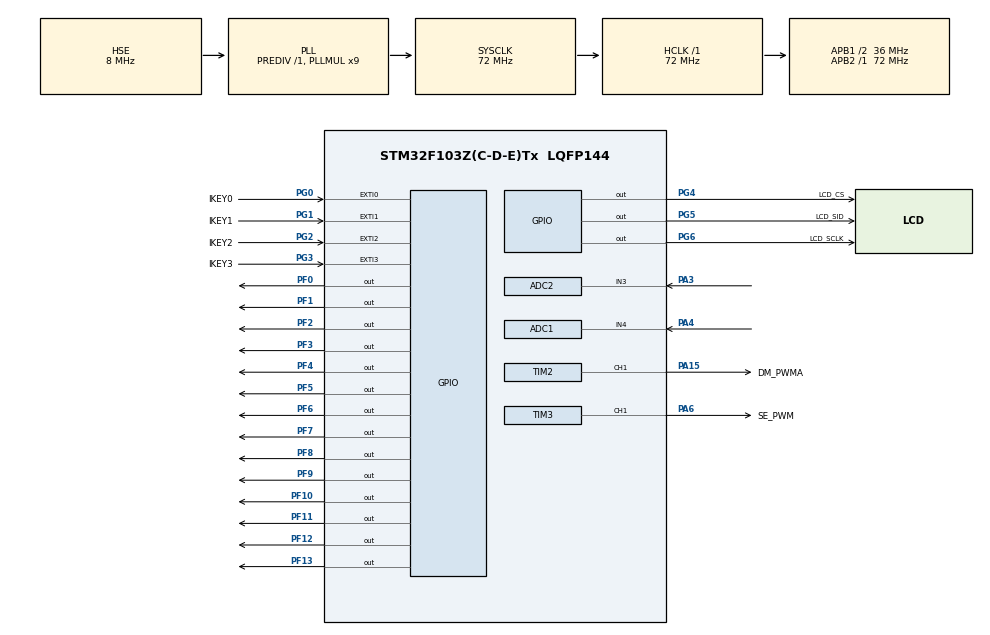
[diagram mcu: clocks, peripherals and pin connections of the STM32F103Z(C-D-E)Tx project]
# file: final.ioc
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ADC1.Channel-9\#ChannelRegularConversion=ADC_CHANNEL_4
ADC1.NbrOfConversionFlag=1
ADC1.Rank-9\#ChannelRegularConversion=1
ADC1.SamplingTime-9\#ChannelRegularConversion=ADC_SAMPLETIME_1CYCLE_5
ADC1.master=1
ADC2.Channel-0\#ChannelRegularConversion=ADC_CHANNEL_3
ADC2.NbrOfConversionFlag=1
ADC2.Rank-0\#ChannelRegularConversion=1
ADC2.SamplingTime-0\#ChannelRegularConversion=ADC_SAMPLETIME_1CYCLE_5
FREERTOS.Queues01=DataUpdateQueue,16,DataUpdateQueueItem,0,Dynamic,NULL,NULL
FREERTOS.Tasks01=default_task,8,128,start_task_default_task,Default,NULL,Dynamic,NULL,NULL;running_lights,10,128,start_task_running_lights,As weak,NULL,Dynamic,NULL,NULL;traffic_lights,10,128,start_task_traffic_lights,As weak,NULL,Dynamic,NULL,NULL;dc_motor,11,128,start_task_dc_motor,As weak,NULL,Dynamic,NULL,NULL;steering_engine,13,128,start_task_steering_engine,As external,NULL,Dynamic,NULL,NULL;lcd12864,14,128,start_task_lcd,As external,NULL,Dynamic,NULL,NULL;adc_pot,8,128,start_task_adc_pot,As external,NULL,Dynamic,NULL,NULL;adc_temp,8,128,start_task_adc_temp,As external,NULL,Dynamic,NULL,NULL
FREERTOS.configTOTAL_HEAP_SIZE=8192
Mcu.Family=STM32F1
Mcu.Name=STM32F103Z(C-D-E)Tx
Mcu.Package=LQFP144
NVIC.EXTI0_IRQn=true\:5\:0\:false\:false\:true\:false\:true\:true\:true
NVIC.EXTI1_IRQn=true\:5\:0\:false\:false\:true\:false\:true\:true\:true
NVIC.EXTI2_IRQn=true\:5\:0\:false\:false\:true\:false\:true\:true\:true
NVIC.EXTI3_IRQn=true\:5\:0\:false\:false\:true\:false\:true\:true\:true
NVIC.PriorityGroup=NVIC_PRIORITYGROUP_4
NVIC.RCC_IRQn=true\:5\:0\:false\:false\:true\:true\:true\:false\:true
NVIC.TIM1_UP_IRQn=true\:15\:0\:false\:false\:true\:false\:false\:true\:true
NVIC.TimeBase=TIM1_UP_IRQn
NVIC.TimeBaseIP=TIM1
OSC_IN.Mode=HSE-External-Oscillator
OSC_IN.Signal=RCC_OSC_IN
OSC_OUT.Mode=HSE-External-Oscillator
OSC_OUT.Signal=RCC_OSC_OUT
PA13.Mode=Serial_Wire
PA13.Signal=SYS_JTMS-SWDIO
PA14.Mode=Serial_Wire
PA14.Signal=SYS_JTCK-SWCLK
PA15.GPIO_Label=DM_PWMA
PA15.Signal=S_TIM2_CH1_ETR
PA3.Signal=ADCx_IN3
PA4.Signal=ADCx_IN4
PA6.GPIO_Label=SE_PWM
PA6.Signal=S_TIM3_CH1
PF0.Signal=GPIO_Output
PF1.Signal=GPIO_Output
PF10.Signal=GPIO_Output
PF11.Signal=GPIO_Output
PF12.Signal=GPIO_Output
PF13.Signal=GPIO_Output
PF2.Signal=GPIO_Output
PF3.Signal=GPIO_Output
PF4.Signal=GPIO_Output
PF5.Signal=GPIO_Output
PF6.Signal=GPIO_Output
PF7.Signal=GPIO_Output
PF8.Signal=GPIO_Output
PF9.Signal=GPIO_Output
PG0.GPIO_Label=IKEY0
PG0.GPIO_ModeDefaultEXTI=GPIO_MODE_IT_FALLING
PG0.Signal=GPXTI0
PG1.GPIO_Label=IKEY1
PG1.GPIO_ModeDefaultEXTI=GPIO_MODE_IT_FALLING
PG1.Signal=GPXTI1
PG2.GPIO_Label=IKEY2
PG2.GPIO_ModeDefaultEXTI=GPIO_MODE_IT_FALLING
PG2.Signal=GPXTI2
PG3.GPIO_Label=IKEY3
PG3.GPIO_ModeDefaultEXTI=GPIO_MODE_IT_FALLING
PG3.Signal=GPXTI3
PG4.GPIO_Label=LCD_CS
PG4.Signal=GPIO_Output
PG5.GPIO_Label=LCD_SID
PG5.Signal=GPIO_Output
PG6.GPIO_Label=LCD_SCLK
PG6.Signal=GPIO_Output
ProjectManager.HeapSize=0x200
ProjectManager.StackSize=0x400
ProjectManager.TargetToolchain=Makefile
RCC.ADCPresc=RCC_ADCPCLK2_DIV6
RCC.AHBFreq_Value=72000000
RCC.APB1CLKDivider=RCC_HCLK_DIV2
RCC.APB1Freq_Value=36000000
RCC.APB1TimFreq_Value=72000000
RCC.APB2Freq_Value=72000000
RCC.APB2TimFreq_Value=72000000
RCC.EnbaleCSS=true
RCC.HCLKFreq_Value=72000000
RCC.PLLMUL=RCC_PLL_MUL9
RCC.PLLSourceVirtual=RCC_PLLSOURCE_HSE
RCC.SYSCLKFreq_VALUE=72000000
RCC.SYSCLKSource=RCC_SYSCLKSOURCE_PLLCLK
RCC.USBFreq_Value=72000000
SH.ADCx_IN3.0=ADC2_IN3,IN3
SH.ADCx_IN4.0=ADC1_IN4,IN4
SH.S_TIM2_CH1_ETR.0=TIM2_CH1,PWM Generation1 CH1
SH.S_TIM3_CH1.0=TIM3_CH1,PWM Generation1 CH1
TIM2.Channel-PWM\ Generation1\ CH1=TIM_CHANNEL_1
TIM2.Period=1000-1
TIM2.Prescaler=72-1
TIM3.Channel-PWM\ Generation1\ CH1=TIM_CHANNEL_1
TIM3.Period=200 - 1
TIM3.Prescaler=7200-1
TIM3.Pulse-PWM\ Generation1\ CH1=0
VP_FREERTOS_VS_CMSIS_V2.Mode=CMSIS_V2
VP_SYS_VS_tim1.Mode=TIM1
board=custom

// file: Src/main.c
/* USER CODE BEGIN Header */
/**
 ******************************************************************************
 * @file           : main.c
 * @brief          : Main program body
 ******************************************************************************
 * @attention
 *
 * Copyright (c) 2024 STMicroelectronics.
 * All rights reserved.
 *
 * This software is licensed under terms that can be found in the LICENSE file
 * in the root directory of this software component.
 * If no LICENSE file comes with this software, it is provided AS-IS.
 *
 ******************************************************************************
 */
/* USER CODE END Header */
#include "main.h"
#include "adc.h"
#include "cmsis_os.h"
#include "gpio.h"
#include "tim.h"

/* USER CODE BEGIN Includes */
#include "cpp_main.hh"
/* USER CODE END Includes */

void SystemClock_Config(void);
void MX_FREERTOS_Init(void);

int main(void) {

  /* MCU Configuration--------------------------------------------------------*/

  /* Reset of all peripherals, Initializes the Flash interface and the Systick.
   */
  HAL_Init();

  /* Configure the system clock */
  SystemClock_Config();

  /* Initialize all configured peripherals */
  MX_GPIO_Init();
  MX_TIM2_Init();
  MX_TIM3_Init();
  MX_ADC1_Init();
  MX_ADC2_Init();
  /* USER CODE BEGIN 2 */
  cpp_main();
  /* USER CODE END 2 */

  /* Init scheduler */
  osKernelInitialize();

  /* Call init function for freertos objects (in cmsis_os2.c) */
  MX_FREERTOS_Init();

  /* Start scheduler */
  osKernelStart();

  /* We should never get here as control is now taken by the scheduler */

  /* Infinite loop */
  while (1) {

  }
}

void SystemClock_Config(void) {
  RCC_OscInitTypeDef RCC_OscInitStruct = {0};
  RCC_ClkInitTypeDef RCC_ClkInitStruct = {0};
  RCC_PeriphCLKInitTypeDef PeriphClkInit = {0};

  /** Initializes the RCC Oscillators according to the specified parameters
   * in the RCC_OscInitTypeDef structure.
   */
  RCC_OscInitStruct.OscillatorType = RCC_OSCILLATORTYPE_HSE;
  RCC_OscInitStruct.HSEState = RCC_HSE_ON;
  RCC_OscInitStruct.HSEPredivValue = RCC_HSE_PREDIV_DIV1;
  RCC_OscInitStruct.HSIState = RCC_HSI_ON;
  RCC_OscInitStruct.PLL.PLLState = RCC_PLL_ON;
  RCC_OscInitStruct.PLL.PLLSource = RCC_PLLSOURCE_HSE;
  RCC_OscInitStruct.PLL.PLLMUL = RCC_PLL_MUL9;
  if (HAL_RCC_OscConfig(&RCC_OscInitStruct) != HAL_OK) {
    Error_Handler();
  }

  /** Initializes the CPU, AHB and APB buses clocks
   */
  RCC_ClkInitStruct.ClockType = RCC_CLOCKTYPE_HCLK | RCC_CLOCKTYPE_SYSCLK |
                                RCC_CLOCKTYPE_PCLK1 | RCC_CLOCKTYPE_PCLK2;
  RCC_ClkInitStruct.SYSCLKSource = RCC_SYSCLKSOURCE_PLLCLK;
  RCC_ClkInitStruct.AHBCLKDivider = RCC_SYSCLK_DIV1;
  RCC_ClkInitStruct.APB1CLKDivider = RCC_HCLK_DIV2;
  RCC_ClkInitStruct.APB2CLKDivider = RCC_HCLK_DIV1;

  if (HAL_RCC_ClockConfig(&RCC_ClkInitStruct, FLASH_LATENCY_2) != HAL_OK) {
    Error_Handler();
  }
  PeriphClkInit.PeriphClockSelection = RCC_PERIPHCLK_ADC;
  PeriphClkInit.AdcClockSelection = RCC_ADCPCLK2_DIV6;
  if (HAL_RCCEx_PeriphCLKConfig(&PeriphClkInit) != HAL_OK) {
    Error_Handler();
  }

  /** Enables the Clock Security System
   */
  HAL_RCC_EnableCSS();
}

void HAL_TIM_PeriodElapsedCallback(TIM_HandleTypeDef *htim) {
  if (htim->Instance == TIM1) {
    HAL_IncTick();
  }
}

void Error_Handler(void) {
  __disable_irq();
  while (1) {
  }
}

#ifdef USE_FULL_ASSERT
/**
 * @brief  Reports the name of the source file and the source line number
 *         where the assert_param error has occurred.
 * @param  file: pointer to the source file name
 * @param  line: assert_param error line source number
 * @retval None
 */
void assert_failed(uint8_t *file, uint32_t line) {
  /* USER CODE BEGIN 6 */
  /* User can add his own implementation to report the file name and line
     number, ex: printf("Wrong parameters value: file %s on line %d\r\n", file,
     line) */
  /* USER CODE END 6 */
}
#endif /* USE_FULL_ASSERT */

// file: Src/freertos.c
/* USER CODE BEGIN Header */
/**
 ******************************************************************************
 * File Name          : freertos.c
 * Description        : Code for freertos applications
 ******************************************************************************
 * @attention
 *
 * Copyright (c) 2024 STMicroelectronics.
 * All rights reserved.
 *
 * This software is licensed under terms that can be found in the LICENSE file
 * in the root directory of this software component.
 * If no LICENSE file comes with this software, it is provided AS-IS.
 *
 ******************************************************************************
 */
/* USER CODE END Header */

#include "FreeRTOS.h"
#include "cmsis_os.h"
#include "main.h"
#include "task.h"

/* USER CODE BEGIN Includes */
#include "data_update_queue.h"
/* USER CODE END Includes */

/* Definitions for default_task */
osThreadId_t default_taskHandle;
const osThreadAttr_t default_task_attributes = {
    .name = "default_task",
    .stack_size = 128 * 4,
    .priority = (osPriority_t)osPriorityLow,
};
/* Definitions for running_lights */
osThreadId_t running_lightsHandle;
const osThreadAttr_t running_lights_attributes = {
    .name = "running_lights",
    .stack_size = 128 * 4,
    .priority = (osPriority_t)osPriorityLow2,
};
/* Definitions for traffic_lights */
osThreadId_t traffic_lightsHandle;
const osThreadAttr_t traffic_lights_attributes = {
    .name = "traffic_lights",
    .stack_size = 128 * 4,
    .priority = (osPriority_t)osPriorityLow2,
};
/* Definitions for dc_motor */
osThreadId_t dc_motorHandle;
const osThreadAttr_t dc_motor_attributes = {
    .name = "dc_motor",
    .stack_size = 128 * 4,
    .priority = (osPriority_t)osPriorityLow3,
};
/* Definitions for steering_engine */
osThreadId_t steering_engineHandle;
const osThreadAttr_t steering_engine_attributes = {
    .name = "steering_engine",
    .stack_size = 128 * 4,
    .priority = (osPriority_t)osPriorityLow5,
};
/* Definitions for lcd12864 */
osThreadId_t lcd12864Handle;
const osThreadAttr_t lcd12864_attributes = {
    .name = "lcd12864",
    .stack_size = 128 * 4,
    .priority = (osPriority_t)osPriorityLow6,
};
/* Definitions for adc_pot */
osThreadId_t adc_potHandle;
const osThreadAttr_t adc_pot_attributes = {
    .name = "adc_pot",
    .stack_size = 128 * 4,
    .priority = (osPriority_t)osPriorityLow,
};
/* Definitions for adc_temp */
osThreadId_t adc_tempHandle;
const osThreadAttr_t adc_temp_attributes = {
    .name = "adc_temp",
    .stack_size = 128 * 4,
    .priority = (osPriority_t)osPriorityLow,
};
/* Definitions for DataUpdateQueue */
osMessageQueueId_t DataUpdateQueueHandle;
const osMessageQueueAttr_t DataUpdateQueue_attributes = {.name =
                                                             "DataUpdateQueue"};

void start_task_default_task(void *argument);
void start_task_running_lights(void *argument);
void start_task_traffic_lights(void *argument);
void start_task_dc_motor(void *argument);
extern void start_task_steering_engine(void *argument);
extern void start_task_lcd(void *argument);
extern void start_task_adc_pot(void *argument);
extern void start_task_adc_temp(void *argument);

void MX_FREERTOS_Init(void); /* (MISRA C 2004 rule 8.1) */

void MX_FREERTOS_Init(void) {

  /* Create the queue(s) */
  /* creation of DataUpdateQueue */
  DataUpdateQueueHandle = osMessageQueueNew(16, sizeof(DataUpdateQueueItem),
                                            &DataUpdateQueue_attributes);

  /* Create the thread(s) */
  /* creation of default_task */
  default_taskHandle =
      osThreadNew(start_task_default_task, NULL, &default_task_attributes);

  /* creation of running_lights */
  running_lightsHandle =
      osThreadNew(start_task_running_lights, NULL, &running_lights_attributes);

  /* creation of traffic_lights */
  traffic_lightsHandle =
      osThreadNew(start_task_traffic_lights, NULL, &traffic_lights_attributes);

  /* creation of dc_motor */
  dc_motorHandle = osThreadNew(start_task_dc_motor, NULL, &dc_motor_attributes);

  /* creation of steering_engine */
  steering_engineHandle = osThreadNew(start_task_steering_engine, NULL,
                                      &steering_engine_attributes);

  /* creation of lcd12864 */
  lcd12864Handle = osThreadNew(start_task_lcd, NULL, &lcd12864_attributes);

  /* creation of adc_pot */
  adc_potHandle = osThreadNew(start_task_adc_pot, NULL, &adc_pot_attributes);

  /* creation of adc_temp */
  adc_tempHandle = osThreadNew(start_task_adc_temp, NULL, &adc_temp_attributes);

}

void start_task_default_task(void *argument) {
  for (;;) {
    osDelay(1);
  }
}

__weak void start_task_running_lights(void *argument) {
  for (;;) {
    osDelay(1);
  }
}

__weak void start_task_traffic_lights(void *argument) {
  for (;;) {
    osDelay(1);
  }
}

__weak void start_task_dc_motor(void *argument) {
  for (;;) {
    osDelay(1);
  }
}
